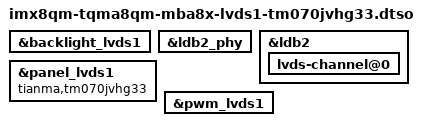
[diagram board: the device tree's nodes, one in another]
// SPDX-License-Identifier: (GPL-2.0-or-later OR MIT)
/*
 * Copyright (c) 2018-2024 TQ-Systems GmbH <linux@ew.tq-group.com>,
 * D-82229 Seefeld, Germany.
 * Author: Alexander Stein
 */

/dts-v1/;
/plugin/;

&backlight_lvds1 {
	status = "okay";
};

&ldb2_phy {
	status = "okay";
};

&ldb2 {
	status = "okay";

	lvds-channel@0 {
		status = "okay";
	};
};

&panel_lvds1 {
	compatible = "tianma,tm070jvhg33";
	status = "okay";
};

&pwm_lvds1 {
	status = "okay";
};
